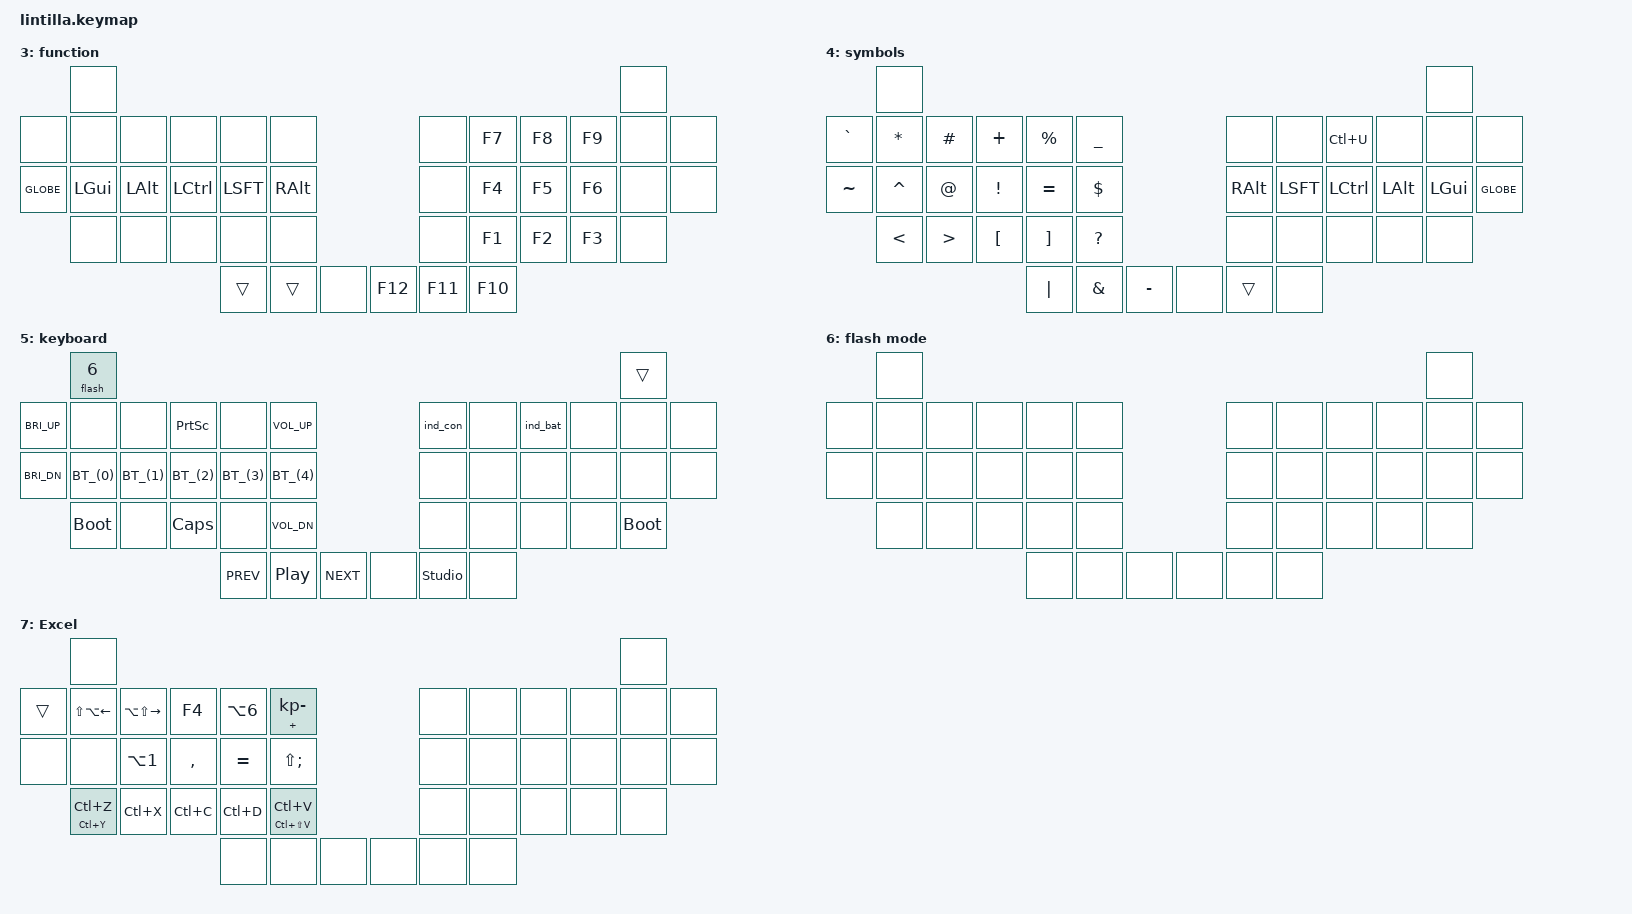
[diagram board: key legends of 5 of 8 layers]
#include <behaviors.dtsi>
#include <dt-bindings/zmk/bt.h>
#include <dt-bindings/zmk/keys.h>
#include <dt-bindings/zmk/outputs.h>
#include <behaviors/rgbled_widget.dtsi>

// Multiple mods
#define GS(key) &kp LG(LS(key))
#define GCS(key) &kp LG(LC(LS(key)))
#define HYPR(key) &kp LG(LA(LC(LS(key))))

// Shortcuts for home row mods
#define Glb &hm GLOBE
#define Sft &hm LSHFT
#define Ctl &hm LCTRL
#define Opt &hm LALT
#define Cmd &hm LGUI
#define Alt &hm RALT

// Magic bluetooth button
#define BT_(btnum) &bt_key btnum btnum

/ {
    behaviors {
        bt_key: magic_bluetooth_key {
            compatible = "zmk,behavior-hold-tap";
            #binding-cells = <2>;
            flavor = "tap-preferred";
            tapping-term-ms = <500>;
            bindings = <&bt_clr>, <&bt_sel>;
        };

        hm: homerow_mod {
            compatible = "zmk,behavior-hold-tap";
            #binding-cells = <2>;
            tapping-term-ms = <300>;
            require-prior-idle-ms = <150>;
            quick-tap-ms = <0>;
            flavor = "tap-preferred";
            bindings = <&kp>, <&kp>;
        };

        lp_mc: launch_pad_mission_control {
            compatible = "zmk,behavior-tap-dance";
            #binding-cells = <0>;
            tapping-term-ms = <200>;
            bindings = <HYPR(N4)>, <&kp LC(UP)>;
        };

        lsscw: layer_sticky_shift_caps_word {
            compatible = "zmk,behavior-hold-tap";
            #binding-cells = <2>;
            flavor = "balanced";
            tapping-term-ms = <200>;
            bindings = <&mo>, <&sscw>;
        };

        mcs: mod_comma_semi {
            compatible = "zmk,behavior-mod-morph";
            #binding-cells = <0>;
            bindings = <&kp COMMA>, <&kp SEMI>;
            mods = <(MOD_LSFT|MOD_RSFT)>;
        };

        mdc: mod_dot_colon {
            compatible = "zmk,behavior-mod-morph";
            #binding-cells = <0>;
            bindings = <&kp DOT>, <&kp COLON>;
            mods = <(MOD_LSFT|MOD_RSFT)>;
        };

        msb: mod_slash_back {
            compatible = "zmk,behavior-mod-morph";
            #binding-cells = <0>;
            bindings = <&kp SLASH>, <&kp BACKSLASH>;
            mods = <(MOD_LSFT|MOD_RSFT)>;
        };

        sscw: sticky_shift_caps_word {
            compatible = "zmk,behavior-mod-morph";
            #binding-cells = <0>;
            bindings = <&sk LSHIFT>, <&caps_word>;
            mods = <(MOD_LSFT|MOD_RSFT)>;
        };
    };

    conditional_layers {
        compatible = "zmk,conditional-layers";
        function_layer {
            if-layers = <1 2>;
            then-layer = <3>;
        };
    };

    macros {
        bt_clr: bluetooth_clear {
            compatible = "zmk,behavior-macro-one-param";
            #binding-cells = <1>;
            bindings = <&macro_param_1to1 &bt_sel MACRO_PLACEHOLDER>, <&bt BT_CLR>;
        };

        bt_sel: bluetooth_select {
            compatible = "zmk,behavior-macro-one-param";
            #binding-cells = <1>;
            bindings = <&out OUT_BLE>, <&macro_param_1to2 &bt BT_SEL MACRO_PLACEHOLDER>;
        };

        flash: dongle_bootloader {
            compatible = "zmk,behavior-macro-one-param";
            #binding-cells = <1>;
            bindings = <&macro_param_1to1 &to MACRO_PLACEHOLDER>, <&bootloader>;
        };
    };

    keymap {
        compatible = "zmk,keymap";

        qwerty {
//                       ┏━━━━━━━━━━━━━━━━━━━━━━━━━┓
            display-name = "Colemak"                ;
//                       ┗━━━━━━━━━━━━━━━━━━━━━━━━━┛
            bindings = <
//         ┏━━━━━━━┓                                                                                          ┏━━━━━━━┓
//         ┃LAUNCHP┃                                                                                          ┃ BKSPC  ┃
            &kp F4                                                                                           &lt 5 BACKSPACE
//         ┃MISSION┃                                                                                          ┃ keybd ┃
// ┏━━━━━━━╋━━━━━━━╋━━━━━━━┳━━━━━━━┳━━━━━━━┳━━━━━━━┓                          ┏━━━━━━━┳━━━━━━━┳━━━━━━━┳━━━━━━━╋━━━━━━━╋━━━━━━━┓
// ┃  ESC  ┃   Q   ┃   W   ┃   F   ┃   P   ┃   B   ┃                          ┃   J   ┃   L   ┃   U   ┃   Y   ┃   ' "   ┃ DELETE ┃
    &lt 7 ESC  &kp Q   &kp W   &kp F   &kp P   &kp B                              &kp J   &kp L   &kp U   &kp Y   &mt LS(NUMBER_2) APOS  &kp DELETE
// ┣━━━━━━━╋━━━━━━━╋━━━━━━━╋━━━━━━━╋━━━━━━━╋━━━━━━━┫                          ┣━━━━━━━╋━━━━━━━╋━━━━━━━╋━━━━━━━╋━━━━━━━╋━━━━━━━┫
// ┃  TAB  ┃   A   ┃   R   ┃   S   ┃   T   ┃   G   ┃                          ┃   M   ┃   N   ┃   E   ┃   I   ┃  O  ┃RETURN ┃
    &mt SPACE TAB  Cmd A   Opt R   Ctl S   Sft T   &mt EQUAL G                      &kp M   Sft N   Ctl E   Opt I  Cmd O  &kp RET
// ┃ Globe ┃ Shift ┃ Ctrl  ┃  Opt  ┃  Cmd  ┃ R Alt ┃                          ┃ R Alt ┃  Cmd  ┃  Opt  ┃ Ctrl  ┃ Shift ┃ Globe ┃
// ┗━━━━━━━╋━━━━━━━╋━━━━━━━╋━━━━━━━╋━━━━━━━╋━━━━━━━┫                          ┣━━━━━━━╋━━━━━━━╋━━━━━━━╋━━━━━━━╋━━━━━━━╋━━━━━━━┛
//         ┃   Z   ┃   X   ┃   C   ┃   D   ┃   V   ┃                          ┃   K   ┃   H   ┃  , ;  ┃  . :  ┃  / \  ┃
             &kp Z   &kp X   &kp C   &kp D   &kp V                              &kp K   &kp H   &mcs    &mdc    &mt NON_US_BACKSLASH FSLH
//         ┗━━━━━━━┻━━━━━━━┻━━━━━━━┻━━━┳━━━┻━━━┳━━━┻━━━┳━━━━━━━┓  ┏━━━━━━━┳━━━┻━━━┳━━━┻━━━┳━━━┻━━━━━━━┻━━━━━━━┻━━━━━━━┛
//                                     ┃ ( num ┃ SHIFT ┃ { cmd ┃  ┃ } cmd ┃ SPACE ┃ ) alt ┃
                             &lt 1 LPAR &lsscw 2 0 &mt NON_US_BACKSLASH COMMA  &mt SLASH PERIOD &lt 4 SPC &mt LALT RPAR
//                                     ┗━━━━━━━┫  nav  ┣━━━━━━━┛  ┗━━━━━━━┫  sym  ┣━━━━━━━┛
//                                             ┗━━━━━━━┛                  ┗━━━━━━━┛
            >;
        };

        num {
//                       ┏━━━━━━━━━━━━━━━━━━━━━━━━━┓
            display-name = "numpad"                ;
//                       ┗━━━━━━━━━━━━━━━━━━━━━━━━━┛
            bindings = <
//         ┏━━━━━━━┓                                                                                          ┏━━━━━━━┓
//         ┃       ┃                                                                                          ┃  DEL  ┃
             &none                                                                                             &kp BSPC
// ┏━━━━━━━╋━━━━━━━╋━━━━━━━┳━━━━━━━┳━━━━━━━┳━━━━━━━┓                          ┏━━━━━━━┳━━━━━━━┳━━━━━━━┳━━━━━━━╋━━━━━━━╋━━━━━━━┓
// ┃       ┃       ┃       ┃       ┃       ┃       ┃                          ┃   -   ┃   7   ┃   8   ┃   9   ┃   /   ┃ BKSPC ┃
     &none   &none   &none   &none   &none   &none                            &kp MINUS &kp N7 &kp N8  &kp N9 &kp SLASH  &kp DELETE
// ┣━━━━━━━╋━━━━━━━╋━━━━━━━╋━━━━━━━╋━━━━━━━╋━━━━━━━┫                          ┣━━━━━━━╋━━━━━━━╋━━━━━━━╋━━━━━━━╋━━━━━━━╋━━━━━━━┫
// ┃       ┃ CtrlA ┃       ┃ CtrlD ┃       ┃       ┃                          ┃   = +   ┃   4   ┃   5   ┃   6   ┃   +   ┃RETURN ┃
     &none Cmd LC(A)  &trans     Ctl LC(S)  &trans     &none                          &mt EQUAL PLUS &kp N4  &kp N5  &kp N6 &kp ASTERISK &kp RET
// ┃ Globe ┃ Shift ┃ Ctrl  ┃  Opt  ┃  Cmd  ┃ R Alt ┃                          ┃       ┃       ┃       ┃       ┃       ┃       ┃
// ┗━━━━━━━╋━━━━━━━╋━━━━━━━╋━━━━━━━╋━━━━━━━╋━━━━━━━┫                          ┣━━━━━━━╋━━━━━━━╋━━━━━━━╋━━━━━━━╋━━━━━━━╋━━━━━━━┛
//         ┃ CtrlZ ┃ CtrlX ┃ CtrlC ┃ CtrlV ┃       ┃                          ┃   : .  ┃   1   ┃   2   ┃   3   ┃   =   ┃
         &kp LC(Z)  &kp LC(X)  &kp LC(C)  &kp LC(D)  &kp LC(V)                        &mt COLON PERIOD &kp N1 &kp N2  &kp N3 &kp EQUAL
//         ┗━━━━━━━┻━━━━━━━┻━━━━━━━┻━━━┳━━━┻━━━┳━━━┻━━━┳━━━━━━━┓  ┏━━━━━━━┳━━━┻━━━┳━━━┻━━━┳━━━┻━━━━━━━┻━━━━━━━┻━━━━━━━┛
//                                     ┃ ##### ┃       ┃       ┃  ┃   .   ┃ SPACE ┃   0   ┃
                                         &trans  &mo 2   &trans    &trans &kp SPC &kp N0
//                                     ┗━━━━━━━┫  fn   ┣━━━━━━━┛  ┗━━━━━━━┫       ┣━━━━━━━┛
//                                             ┗━━━━━━━┛                  ┗━━━━━━━┛
            >;
        };

        nav {
//                       ┏━━━━━━━━━━━━━━━━━━━━━━━━━┓
            display-name = "navigation"            ;
//                       ┗━━━━━━━━━━━━━━━━━━━━━━━━━┛
            bindings = <
//         ┏━━━━━━━┓                                                                                          ┏━━━━━━━┓
//         ┃       ┃                                                                                          ┃  DEL  ┃
             &none                                                                                             &kp BSPC
// ┏━━━━━━━╋━━━━━━━╋━━━━━━━┳━━━━━━━┳━━━━━━━┳━━━━━━━┓                          ┏━━━━━━━┳━━━━━━━┳━━━━━━━┳━━━━━━━╋━━━━━━━╋━━━━━━━┓
// ┃       ┃       ┃       ┃       ┃       ┃       ┃                          ┃ Pg Up ┃       ┃       ┃       ┃       ┃ BKSPC ┃
     &none   &none   &none   &none   &none   &none                           &kp PG_UP    &kp HOME &none   &none   &none  &kp DELETE
// ┣━━━━━━━╋━━━━━━━╋━━━━━━━╋━━━━━━━╋━━━━━━━╋━━━━━━━┫                          ┣━━━━━━━╋━━━━━━━╋━━━━━━━╋━━━━━━━╋━━━━━━━╋━━━━━━━┫
// ┃       ┃ Cmd A ┃       ┃       ┃       ┃       ┃                          ┃ Home  ┃ Left  ┃  Up   ┃ Right ┃  End  ┃RETURN ┃
     &none  Cmd LC(A) &trans  Ctl LC(S) &trans   &none                        &none        &kp LEFT &kp UP  &kp RIGHT &none &kp RET
// ┃ Globe ┃ Shift ┃ Ctrl  ┃  Opt  ┃  Cmd  ┃ R Alt ┃                          ┃       ┃       ┃       ┃       ┃       ┃       ┃
// ┗━━━━━━━╋━━━━━━━╋━━━━━━━╋━━━━━━━╋━━━━━━━╋━━━━━━━┫                          ┣━━━━━━━╋━━━━━━━╋━━━━━━━╋━━━━━━━╋━━━━━━━╋━━━━━━━┛
//         ┃ Cmd Z ┃ Cmd X ┃ Cmd C ┃ Cmd V ┃       ┃                          ┃ Pg Dn ┃       ┃ Down  ┃       ┃       ┃
         &kp LC(Z) &kp LC(X) &kp LC(C) &kp LC(D) &kp LC(LS(V))               &kp PG_DN    &kp END  &kp DOWN &none   &none
//         ┗━━━━━━━┻━━━━━━━┻━━━━━━━┻━━━┳━━━┻━━━┳━━━┻━━━┳━━━━━━━┓  ┏━━━━━━━┳━━━┻━━━┳━━━┻━━━┳━━━┻━━━━━━━┻━━━━━━━┻━━━━━━━┛
//                                     ┃  fn   ┃ ##### ┃       ┃  ┃       ┃ SPACE ┃       ┃
                                         &mo 1   &trans  &none      &none  &kp SPC  &none
//                                     ┗━━━━━━━┫       ┣━━━━━━━┛  ┗━━━━━━━┫       ┣━━━━━━━┛
//                                             ┗━━━━━━━┛                  ┗━━━━━━━┛
            >;
        };

        fn {
//                       ┏━━━━━━━━━━━━━━━━━━━━━━━━━┓
            display-name = "function"              ;
//                       ┗━━━━━━━━━━━━━━━━━━━━━━━━━┛
            bindings = <
//         ┏━━━━━━━┓                                                                                          ┏━━━━━━━┓
//         ┃       ┃                                                                                          ┃       ┃
             &none                                                                                              &none
// ┏━━━━━━━╋━━━━━━━╋━━━━━━━┳━━━━━━━┳━━━━━━━┳━━━━━━━┓                          ┏━━━━━━━┳━━━━━━━┳━━━━━━━┳━━━━━━━╋━━━━━━━╋━━━━━━━┓
// ┃       ┃       ┃       ┃       ┃       ┃       ┃                          ┃       ┃  F7   ┃  F8   ┃  F9   ┃       ┃       ┃
     &none   &none   &none   &none   &none   &none                              &none  &kp F7  &kp F8  &kp F9   &none   &none
// ┣━━━━━━━╋━━━━━━━╋━━━━━━━╋━━━━━━━╋━━━━━━━╋━━━━━━━┫                          ┣━━━━━━━╋━━━━━━━╋━━━━━━━╋━━━━━━━╋━━━━━━━╋━━━━━━━┫
// ┃ Globe ┃ Shift ┃ Ctrl  ┃  Opt  ┃  Cmd  ┃ R Alt ┃                          ┃       ┃  F4   ┃  F5   ┃  F6   ┃       ┃       ┃
&kp GLOBE &kp LGUI &kp LALT &kp LCTL &kp LSFT &kp RALT                          &none  &kp F4  &kp F5  &kp F6   &none   &none
// ┗━━━━━━━╋━━━━━━━╋━━━━━━━╋━━━━━━━╋━━━━━━━╋━━━━━━━┫                          ┣━━━━━━━╋━━━━━━━╋━━━━━━━╋━━━━━━━╋━━━━━━━╋━━━━━━━┛
//         ┃       ┃       ┃       ┃       ┃       ┃                          ┃       ┃  F1   ┃  F2   ┃  F3   ┃       ┃
             &none   &none   &none   &none   &none                              &none  &kp F1  &kp F2  &kp F3   &none
//         ┗━━━━━━━┻━━━━━━━┻━━━━━━━┻━━━┳━━━┻━━━┳━━━┻━━━┳━━━━━━━┓  ┏━━━━━━━┳━━━┻━━━┳━━━┻━━━┳━━━┻━━━━━━━┻━━━━━━━┻━━━━━━━┛
//                                     ┃ ##### ┃ ##### ┃       ┃  ┃  F12  ┃  F11  ┃  F10  ┃
                                         &trans  &trans  &none     &kp F12 &kp F11 &kp F10
//                                     ┗━━━━━━━┫       ┣━━━━━━━┛  ┗━━━━━━━┫       ┣━━━━━━━┛
//                                             ┗━━━━━━━┛                  ┗━━━━━━━┛
            >;
        };

        sym {
//                       ┏━━━━━━━━━━━━━━━━━━━━━━━━━┓
            display-name = "symbols"               ;
//                       ┗━━━━━━━━━━━━━━━━━━━━━━━━━┛
            bindings = <
//         ┏━━━━━━━┓                                                                                          ┏━━━━━━━┓
//         ┃       ┃                                                                                          ┃       ┃
             &none                                                                                              &none
// ┏━━━━━━━╋━━━━━━━╋━━━━━━━┳━━━━━━━┳━━━━━━━┳━━━━━━━┓                          ┏━━━━━━━┳━━━━━━━┳━━━━━━━┳━━━━━━━╋━━━━━━━╋━━━━━━━┓
// ┃   `   ┃   *   ┃   #   ┃   +   ┃   %   ┃   _   ┃                          ┃       ┃ CtrlU ┃       ┃       ┃       ┃       ┃
&kp GRAVE &kp STAR &kp HASH &kp PLUS &kp PRCNT &kp UNDER                        &none &none &kp LC(U)   &none   &none   &none
// ┣━━━━━━━╋━━━━━━━╋━━━━━━━╋━━━━━━━╋━━━━━━━╋━━━━━━━┫                          ┣━━━━━━━╋━━━━━━━╋━━━━━━━╋━━━━━━━╋━━━━━━━╋━━━━━━━┫
// ┃   ~   ┃   ^   ┃   @   ┃   !   ┃   =   ┃   $   ┃                          ┃ R Alt ┃  Cmd  ┃  Opt  ┃ Ctrl  ┃       ┃ Globe ┃
&kp TILDE &kp CARET &kp AT &kp EXCL &kp EQUAL &kp DLLR                      &kp RALT &kp LSFT &kp LCTL &kp LALT &kp LGUI &kp GLOBE
// ┗━━━━━━━╋━━━━━━━╋━━━━━━━╋━━━━━━━╋━━━━━━━╋━━━━━━━┫                          ┣━━━━━━━╋━━━━━━━╋━━━━━━━╋━━━━━━━╋━━━━━━━╋━━━━━━━┛
//         ┃   <   ┃   >   ┃   [   ┃   ]   ┃   ?   ┃                          ┃       ┃       ┃       ┃       ┃       ┃
             &kp LT &kp GT &kp LBKT &kp RBKT &kp QMARK                          &none   &none   &none   &none   &none
//         ┗━━━━━━━┻━━━━━━━┻━━━━━━━┻━━━┳━━━┻━━━┳━━━┻━━━┳━━━━━━━┓  ┏━━━━━━━┳━━━┻━━━┳━━━┻━━━┳━━━┻━━━━━━━┻━━━━━━━┻━━━━━━━┛
//                                     ┃   |   ┃   &   ┃   -   ┃  ┃       ┃ ##### ┃       ┃
                                      &kp PIPE &kp AMPS &kp MINUS   &none   &trans  &none
//                                     ┗━━━━━━━┫       ┣━━━━━━━┛  ┗━━━━━━━┫       ┣━━━━━━━┛
//                                             ┗━━━━━━━┛                  ┗━━━━━━━┛
            >;
        };

        keybd {
//                       ┏━━━━━━━━━━━━━━━━━━━━━━━━━┓
            display-name = "keyboard"              ;
//                       ┗━━━━━━━━━━━━━━━━━━━━━━━━━┛
            bindings = <
//         ┏━━━━━━━┓                                                                                          ┏━━━━━━━┓
//         ┃ dongle┃                                                                                          ┃ ##### ┃
           &flash 6                                                                                              &trans
// ┏━━━━━━━╋━━━━━━━╋━━━━━━━┳━━━━━━━┳━━━━━━━┳━━━━━━━┓                          ┏━━━━━━━┳━━━━━━━┳━━━━━━━┳━━━━━━━╋━━━━━━━╋━━━━━━━┓
// ┃ brt + ┃       ┃       ┃scrnsht┃scrn cp┃ vol + ┃                         ┃con led┃       ┃bat led┃       ┃       ┃       ┃
&kp C_BRI_UP &none   &none  &kp PRINTSCREEN &none &kp C_VOL_UP                  &ind_con  &none &ind_bat  &none   &none   &none
// ┣━━━━━━━╋━━━━━━━╋━━━━━━━╋━━━━━━━╋━━━━━━━╋━━━━━━━┫                          ┣━━━━━━━╋━━━━━━━╋━━━━━━━╋━━━━━━━╋━━━━━━━╋━━━━━━━┫
// ┃ brt - ┃  BT1  ┃  BT2  ┃  BT3  ┃  BT4  ┃  BT5  ┃                          ┃       ┃       ┃       ┃       ┃       ┃       ┃
&kp C_BRI_DN BT_(0)  BT_(1)  BT_(2)  BT_(3)  BT_(4)                             &none   &none   &none   &none   &none   &none
// ┗━━━━━━━╋━━━━━━━╋━━━━━━━╋━━━━━━━╋━━━━━━━╋━━━━━━━┫                          ┣━━━━━━━╋━━━━━━━╋━━━━━━━╋━━━━━━━╋━━━━━━━╋━━━━━━━┛
//         ┃ flash ┃       ┃caps lk┃       ┃ vol - ┃                          ┃       ┃       ┃       ┃       ┃ flash ┃
        &bootloader &none &kp CAPS &none &kp C_VOL_DN                           &none   &none   &none   &none &bootloader
//         ┗━━━━━━━┻━━━━━━━┻━━━━━━━┻━━━┳━━━┻━━━┳━━━┻━━━┳━━━━━━━┓  ┏━━━━━━━┳━━━┻━━━┳━━━┻━━━┳━━━┻━━━━━━━┻━━━━━━━┻━━━━━━━┛
//                                     ┃ prev  ┃ play  ┃ next  ┃  ┃       ┃studio ┃       ┃
                                   &kp C_PREV &kp C_PP &kp C_NEXT &none &studio_unlock &none
//                                     ┗━━━━━━━┫       ┣━━━━━━━┛  ┗━━━━━━━┫ unlock┣━━━━━━━┛
//                                             ┗━━━━━━━┛                  ┗━━━━━━━┛
            >;
        };

        flash {
//                       ┏━━━━━━━━━━━━━━━━━━━━━━━━━┓
            display-name = "flash mode"            ;
//                       ┗━━━━━━━━━━━━━━━━━━━━━━━━━┛
            bindings = <
//         ┏━━━━━━━┓                                                                                          ┏━━━━━━━┓
//         ┃       ┃                                                                                          ┃       ┃
             &none                                                                                              &none
// ┏━━━━━━━╋━━━━━━━╋━━━━━━━┳━━━━━━━┳━━━━━━━┳━━━━━━━┓                          ┏━━━━━━━┳━━━━━━━┳━━━━━━━┳━━━━━━━╋━━━━━━━╋━━━━━━━┓
// ┃       ┃       ┃       ┃       ┃       ┃       ┃                          ┃       ┃       ┃       ┃       ┃       ┃       ┃
     &none   &none   &none   &none   &none   &none                              &none   &none   &none   &none   &none   &none
// ┣━━━━━━━╋━━━━━━━╋━━━━━━━╋━━━━━━━╋━━━━━━━╋━━━━━━━┫                          ┣━━━━━━━╋━━━━━━━╋━━━━━━━╋━━━━━━━╋━━━━━━━╋━━━━━━━┫
// ┃       ┃       ┃       ┃       ┃       ┃       ┃                          ┃       ┃       ┃       ┃       ┃       ┃       ┃
     &none   &none   &none   &none   &none   &none                              &none   &none   &none   &none   &none   &none
// ┗━━━━━━━╋━━━━━━━╋━━━━━━━╋━━━━━━━╋━━━━━━━╋━━━━━━━┫                          ┣━━━━━━━╋━━━━━━━╋━━━━━━━╋━━━━━━━╋━━━━━━━╋━━━━━━━┛
//         ┃       ┃       ┃       ┃       ┃       ┃                          ┃       ┃       ┃       ┃       ┃       ┃
             &none   &none   &none   &none   &none                              &none   &none   &none   &none   &none
//         ┗━━━━━━━┻━━━━━━━┻━━━━━━━┻━━━┳━━━┻━━━┳━━━┻━━━┳━━━━━━━┓  ┏━━━━━━━┳━━━┻━━━┳━━━┻━━━┳━━━┻━━━━━━━┻━━━━━━━┻━━━━━━━┛
//                                     ┃       ┃       ┃       ┃  ┃       ┃       ┃       ┃
                                         &none   &none   &none      &none   &none   &none
//                                     ┗━━━━━━━┫       ┣━━━━━━━┛  ┗━━━━━━━┫       ┣━━━━━━━┛
//                                             ┗━━━━━━━┛                  ┗━━━━━━━┛
            >;
        };

        Excel {
//                       ┏━━━━━━━━━━━━━━━━━━━━━━━━━┓
            display-name = "Excel"            ;
//                       ┗━━━━━━━━━━━━━━━━━━━━━━━━━┛
            bindings = <
//         ┏━━━━━━━┓                                                                                          ┏━━━━━━━┓
//         ┃       ┃                                                                                          ┃       ┃
             &none                                                                                              &none
// ┏━━━━━━━╋━━━━━━━╋━━━━━━━┳━━━━━━━┳━━━━━━━┳━━━━━━━┓                          ┏━━━━━━━┳━━━━━━━┳━━━━━━━┳━━━━━━━╋━━━━━━━╋━━━━━━━┓
// ┃       ┃       ┃       ┃       ┃       ┃       ┃                          ┃       ┃       ┃       ┃       ┃       ┃       ┃
     &trans   &kp LS(LA(LEFT))  &kp LA(LS(RIGHT))  &kp F4     &kp LA(NUMBER_6)  &mt PLUS KP_MINUS                              &none   &none   &none   &none   &none   &none
// ┣━━━━━━━╋━━━━━━━╋━━━━━━━╋━━━━━━━╋━━━━━━━╋━━━━━━━┫                          ┣━━━━━━━╋━━━━━━━╋━━━━━━━╋━━━━━━━╋━━━━━━━╋━━━━━━━┫
// ┃       ┃       ┃       ┃       ┃       ┃       ┃                          ┃       ┃       ┃       ┃       ┃       ┃       ┃
     &none   &none   &kp LA(NUMBER_1)   &kp COMMA  &kp EQUAL         &kp LS(SEMI)                                &none   &none   &none   &none   &none   &none
// ┗━━━━━━━╋━━━━━━━╋━━━━━━━╋━━━━━━━╋━━━━━━━╋━━━━━━━┫                          ┣━━━━━━━╋━━━━━━━╋━━━━━━━╋━━━━━━━╋━━━━━━━╋━━━━━━━┛
//         ┃       ┃       ┃       ┃       ┃       ┃                          ┃       ┃       ┃       ┃       ┃       ┃
             &mt LC(Y) LC(Z)   &kp LC(X)          &kp LC(C)  &kp LC(D)         &mt LC(LS(V)) LC(V)                              &none   &none   &none   &none   &none
//         ┗━━━━━━━┻━━━━━━━┻━━━━━━━┻━━━┳━━━┻━━━┳━━━┻━━━┳━━━━━━━┓  ┏━━━━━━━┳━━━┻━━━┳━━━┻━━━┳━━━┻━━━━━━━┻━━━━━━━┻━━━━━━━┛
//                                     ┃       ┃       ┃       ┃  ┃       ┃       ┃       ┃
                                         &none   &none   &none      &none   &none   &none
//                                     ┗━━━━━━━┫       ┣━━━━━━━┛  ┗━━━━━━━┫       ┣━━━━━━━┛
//                                             ┗━━━━━━━┛                  ┗━━━━━━━┛
            >;
        };
        // Extra empty layers for ZMK Studio

        layer8 {
            status = "reserved";
        };
        layer9 {
            status = "reserved";
        };

        layer10 {
            status = "reserved";
        };

        layer11 {
            status = "reserved";
        };

        layer12 {
            status = "reserved";
        };

        layer13 {
            status = "reserved";
        };

        layer14 {
            status = "reserved";
        };

        layer15 {
            status = "reserved";
        };
    };
};

// vim: expandtab softtabstop=4 shiftwidth=4 filetype=dts
